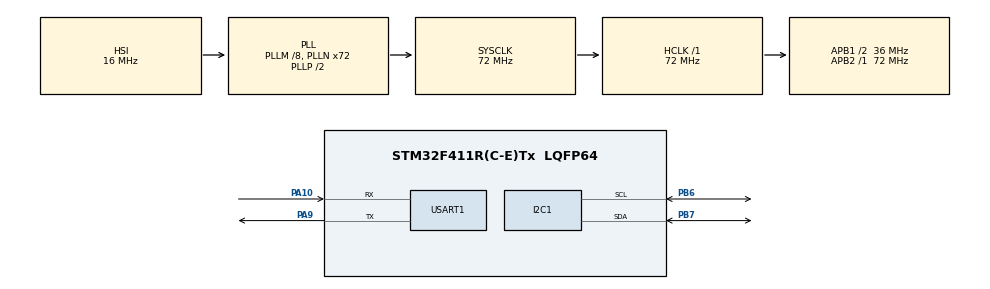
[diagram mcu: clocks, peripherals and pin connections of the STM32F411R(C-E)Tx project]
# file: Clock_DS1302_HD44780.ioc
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Mcu.Family=STM32F4
Mcu.Name=STM32F411R(C-E)Tx
Mcu.Package=LQFP64
NVIC.I2C1_ER_IRQn=true\:0\:0\:false\:false\:true\:true\:true\:true
NVIC.I2C1_EV_IRQn=true\:0\:0\:false\:false\:true\:true\:true\:true
NVIC.PriorityGroup=NVIC_PRIORITYGROUP_4
PA10.Mode=Asynchronous
PA10.Signal=USART1_RX
PA13.Mode=Serial_Wire
PA13.Signal=SYS_JTMS-SWDIO
PA14.Mode=Serial_Wire
PA14.Signal=SYS_JTCK-SWCLK
PA9.Mode=Asynchronous
PA9.Signal=USART1_TX
PB6.GPIO_Speed=GPIO_SPEED_FREQ_LOW
PB6.Mode=I2C
PB6.Signal=I2C1_SCL
PB7.GPIO_Speed=GPIO_SPEED_FREQ_LOW
PB7.Mode=I2C
PB7.Signal=I2C1_SDA
PH0\ -\ OSC_IN.Mode=HSE-External-Clock-Source
PH0\ -\ OSC_IN.Signal=RCC_OSC_IN
PH1\ -\ OSC_OUT.Mode=HSE-External-Clock-Source
PH1\ -\ OSC_OUT.Signal=RCC_OSC_OUT
ProjectManager.HeapSize=0x200
ProjectManager.StackSize=0x400
ProjectManager.TargetToolchain=STM32CubeIDE
RCC.48MHZClocksFreq_Value=36000000
RCC.AHBFreq_Value=72000000
RCC.APB1CLKDivider=RCC_HCLK_DIV2
RCC.APB1Freq_Value=36000000
RCC.APB1TimFreq_Value=72000000
RCC.APB2Freq_Value=72000000
RCC.APB2TimFreq_Value=72000000
RCC.CortexFreq_Value=72000000
RCC.HCLKFreq_Value=72000000
RCC.HSE_VALUE=25000000
RCC.HSI_VALUE=16000000
RCC.LSE_VALUE=32768
RCC.PLLM=8
RCC.PLLN=72
RCC.SYSCLKFreq_VALUE=72000000
RCC.SYSCLKSource=RCC_SYSCLKSOURCE_PLLCLK
RCC.VCOOutputFreq_Value=144000000
USART1.VirtualMode=VM_ASYNC
board=custom

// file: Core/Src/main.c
/* USER CODE BEGIN Header */
/**
  ******************************************************************************
  * @file           : main.c
  * @brief          : Main program body
  ******************************************************************************
  * @attention
  *
  * Copyright (c) 2023 STMicroelectronics.
  * All rights reserved.
  *
  * This software is licensed under terms that can be found in the LICENSE file
  * in the root directory of this software component.
  * If no LICENSE file comes with this software, it is provided AS-IS.
  *
  *
  *Connect PINs:
  *PA8 - CLK
  *PA11 - RST(CE?)
  *PA12 - SDA
  *
  *
  ******************************************************************************
  */
/* USER CODE END Header */
#include "main.h"

/* USER CODE BEGIN Includes */
#include "DS1302.h"
/* USER CODE END Includes */

I2C_HandleTypeDef hi2c1;

UART_HandleTypeDef huart1;

uint8_t buf[7] = {23, 7, 30, 18, 58, 0, 7};
ds1302_date RTC_date;
ds1302_time RTC_time;

void SystemClock_Config(void);
static void MX_GPIO_Init(void);
static void MX_I2C1_Init(void);
static void MX_USART1_UART_Init(void);

int main(void)
{

  /* MCU Configuration--------------------------------------------------------*/

  /* Reset of all peripherals, Initializes the Flash interface and the Systick. */
   HAL_Init();

  /* Configure the system clock */
  SystemClock_Config();

  /* Initialize all configured peripherals */
  MX_GPIO_Init();
  MX_I2C1_Init();
  MX_USART1_UART_Init();
  /* USER CODE BEGIN 2 */
  ds1302_init();
  HAL_Delay(10);
//  DS1302_WriteClock((uint8_t *)buf);
//  HAL_Delay(10);
  RTC_time.hour = 20;
  RTC_time.minutes = 5;
  RTC_time.second = 0;
  RTC_time.time_format = TIME_FORMAT_24HRS;

  ds1302_set_time(&RTC_time);
  /* USER CODE END 2 */

  /* Infinite loop */
  while (1)
  {

    /* USER CODE BEGIN 3 */

	  ds1302_get_time(&RTC_time);

//	  HAL_UART_Transmit(&huart1, &RTC_time, 4, 1000);
// 	  DS1302_ReadTime((uint8_t *)buf);
// 	  HAL_Delay(1000);

//	  HAL_UART_Transmit(&huart1, (uint8_t *) buf, 2, 1000);
//	  HAL_Delay(1000);
//	  HAL_UART_Transmit(&huart1, (uint8_t *) (buf+1), 2, 1000);
//	  HAL_Delay(1000);
//	  HAL_UART_Transmit(&huart1, (uint8_t *) (buf+2), 2, 1000);

  }
  /* USER CODE END 3 */
}

void SystemClock_Config(void)
{
  RCC_OscInitTypeDef RCC_OscInitStruct = {0};
  RCC_ClkInitTypeDef RCC_ClkInitStruct = {0};

  /** Configure the main internal regulator output voltage
  */
  __HAL_RCC_PWR_CLK_ENABLE();
  __HAL_PWR_VOLTAGESCALING_CONFIG(PWR_REGULATOR_VOLTAGE_SCALE1);

  /** Initializes the RCC Oscillators according to the specified parameters
  * in the RCC_OscInitTypeDef structure.
  */
  RCC_OscInitStruct.OscillatorType = RCC_OSCILLATORTYPE_HSI;
  RCC_OscInitStruct.HSIState = RCC_HSI_ON;
  RCC_OscInitStruct.HSICalibrationValue = RCC_HSICALIBRATION_DEFAULT;
  RCC_OscInitStruct.PLL.PLLState = RCC_PLL_ON;
  RCC_OscInitStruct.PLL.PLLSource = RCC_PLLSOURCE_HSI;
  RCC_OscInitStruct.PLL.PLLM = 8;
  RCC_OscInitStruct.PLL.PLLN = 72;
  RCC_OscInitStruct.PLL.PLLP = RCC_PLLP_DIV2;
  RCC_OscInitStruct.PLL.PLLQ = 4;
  if (HAL_RCC_OscConfig(&RCC_OscInitStruct) != HAL_OK)
  {
    Error_Handler();
  }

  /** Initializes the CPU, AHB and APB buses clocks
  */
  RCC_ClkInitStruct.ClockType = RCC_CLOCKTYPE_HCLK|RCC_CLOCKTYPE_SYSCLK
                              |RCC_CLOCKTYPE_PCLK1|RCC_CLOCKTYPE_PCLK2;
  RCC_ClkInitStruct.SYSCLKSource = RCC_SYSCLKSOURCE_PLLCLK;
  RCC_ClkInitStruct.AHBCLKDivider = RCC_SYSCLK_DIV1;
  RCC_ClkInitStruct.APB1CLKDivider = RCC_HCLK_DIV2;
  RCC_ClkInitStruct.APB2CLKDivider = RCC_HCLK_DIV1;

  if (HAL_RCC_ClockConfig(&RCC_ClkInitStruct, FLASH_LATENCY_2) != HAL_OK)
  {
    Error_Handler();
  }
}

static void MX_I2C1_Init(void)
{

  hi2c1.Instance = I2C1;
  hi2c1.Init.ClockSpeed = 100000;
  hi2c1.Init.DutyCycle = I2C_DUTYCYCLE_2;
  hi2c1.Init.OwnAddress1 = 0;
  hi2c1.Init.AddressingMode = I2C_ADDRESSINGMODE_7BIT;
  hi2c1.Init.DualAddressMode = I2C_DUALADDRESS_DISABLE;
  hi2c1.Init.OwnAddress2 = 0;
  hi2c1.Init.GeneralCallMode = I2C_GENERALCALL_DISABLE;
  hi2c1.Init.NoStretchMode = I2C_NOSTRETCH_DISABLE;
  if (HAL_I2C_Init(&hi2c1) != HAL_OK)
  {
    Error_Handler();
  }

}

static void MX_USART1_UART_Init(void)
{

  huart1.Instance = USART1;
  huart1.Init.BaudRate = 115200;
  huart1.Init.WordLength = UART_WORDLENGTH_8B;
  huart1.Init.StopBits = UART_STOPBITS_1;
  huart1.Init.Parity = UART_PARITY_NONE;
  huart1.Init.Mode = UART_MODE_TX_RX;
  huart1.Init.HwFlowCtl = UART_HWCONTROL_NONE;
  huart1.Init.OverSampling = UART_OVERSAMPLING_16;
  if (HAL_UART_Init(&huart1) != HAL_OK)
  {
    Error_Handler();
  }

}

static void MX_GPIO_Init(void)
{

  /* GPIO Ports Clock Enable */
  __HAL_RCC_GPIOH_CLK_ENABLE();
  __HAL_RCC_GPIOA_CLK_ENABLE();
  __HAL_RCC_GPIOB_CLK_ENABLE();

}

void Error_Handler(void)
{
  __disable_irq();
  while (1)
  {
  }
}
